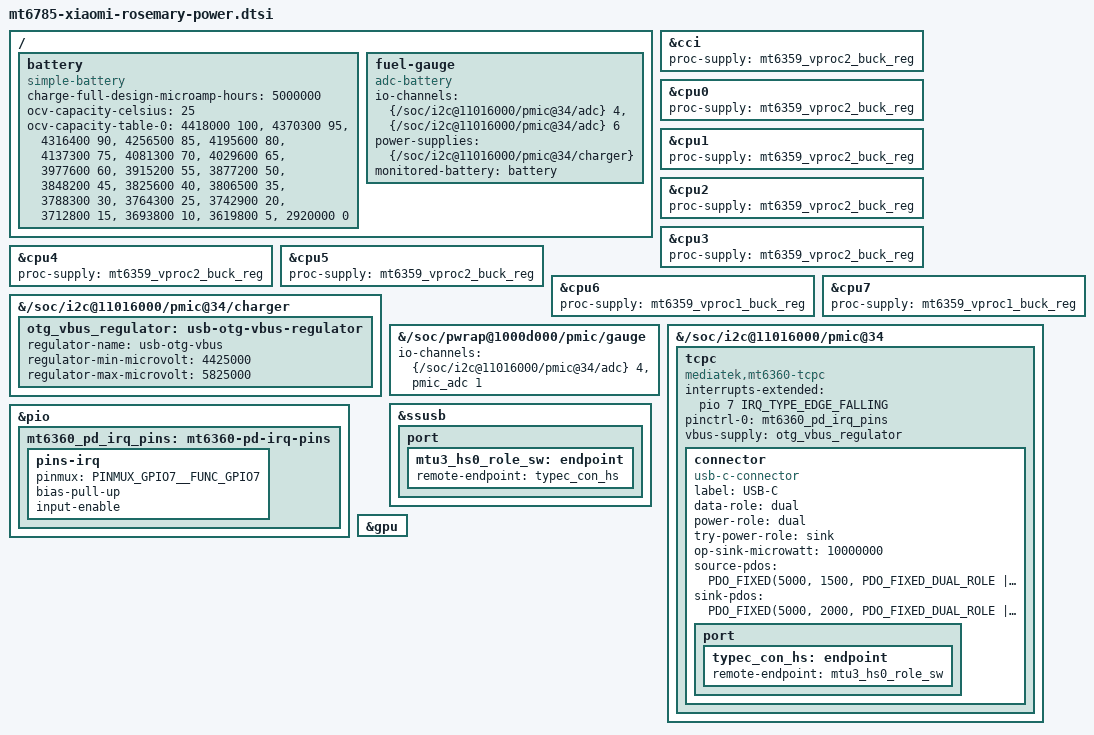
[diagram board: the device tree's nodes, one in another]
// SPDX-License-Identifier: GPL-2.0-only
/*
 * Poco M5s (rosemary): board nodes of the power area (poco-m5s/plan-full-phone.md, Task 0.3).
 * Included at the end of mt6785-xiaomi-rosemary.dts.
 */

#include <dt-bindings/usb/pd.h>

/ {
	/*
	 * The pack: 5000 mAh design (the stock gauge reported 4797 mAh full, 12.11.2026). OCV table:
	 * the vendor profile battery0_profile_t1 (25 C) of the live stock DT (bat_gm30), sampled at 5 %
	 * steps, the same table poco-charge-limit uses.
	 */
	battery: battery {
		compatible = "simple-battery";
		charge-full-design-microamp-hours = <5000000>;
		ocv-capacity-celsius = <25>;
		ocv-capacity-table-0 = <4418000 100>, <4370300 95>, <4316400 90>, <4256500 85>,
				       <4195600 80>, <4137300 75>, <4081300 70>, <4029600 65>,
				       <3977600 60>, <3915200 55>, <3877200 50>, <3848200 45>,
				       <3825600 40>, <3806500 35>, <3788300 30>, <3764300 25>,
				       <3742900 20>, <3712800 15>, <3693800 10>, <3619800 5>,
				       <2920000 0>;
	};

	/*
	 * Battery voltage and current until the MT6359 coulomb counter lands: the MT6360 ADC's VBAT and
	 * IBAT channels (drivers/iio/adc/mt6360-adc.c enum: VBAT = 4, IBAT = 6), read on the phone
	 * 15.11.2026 as 4.376 V and 0 A with the charger reporting Full.
	 */
	fuel-gauge {
		compatible = "adc-battery";
		io-channels = <&{/soc/i2c@11016000/pmic@34/adc} 4>, <&{/soc/i2c@11016000/pmic@34/adc} 6>;
		io-channel-names = "voltage", "current";
		power-supplies = <&{/soc/i2c@11016000/pmic@34/charger}>;
		monitored-battery = <&battery>;
	};
};

/*
 * CPU and CCI supplies, as the begonia board on the same SoC and PMIC wires them
 * (mt6785-xiaomi-begonia-common.dtsi): little cores 0-5 and the CCI on MT6359 VPROC2 ("vproc_l" in
 * the rosemary dts), big cores 6-7 on VPROC1 ("vproc_b"). Without them mediatek-cpufreq and
 * mtk-ccifreq never probe (no cpufreq on the phone, ccifreq deferred, 15.11.2026).
 */
&cci { proc-supply = <&mt6359_vproc2_buck_reg>; };
&cpu0 { proc-supply = <&mt6359_vproc2_buck_reg>; };
&cpu1 { proc-supply = <&mt6359_vproc2_buck_reg>; };
&cpu2 { proc-supply = <&mt6359_vproc2_buck_reg>; };
&cpu3 { proc-supply = <&mt6359_vproc2_buck_reg>; };
&cpu4 { proc-supply = <&mt6359_vproc2_buck_reg>; };
&cpu5 { proc-supply = <&mt6359_vproc2_buck_reg>; };
&cpu6 { proc-supply = <&mt6359_vproc1_buck_reg>; };
&cpu7 { proc-supply = <&mt6359_vproc1_buck_reg>; };

/*
 * USB Type-C: the MT6360 TCPC (I2C5 0x4e in the vendor DT, usb_type_c@4e; its PD interrupt on GPIO7,
 * live DT type_c_port0 mt6360pd,intr_gpio = <&pio 7 0>) drives the role switch of the USB controller
 * and the OTG boost of the MT6360 charger. Written as on begonia (mt6785-xiaomi-begonia-common.dtsi),
 * the same SoC with the same MT6360: dual role, sink preferred, 5 V only both ways. Without it the
 * port is fixed to peripheral and USB OTG cannot work.
 */
&{/soc/i2c@11016000/pmic@34/charger} {
	otg_vbus_regulator: usb-otg-vbus-regulator {
		regulator-name = "usb-otg-vbus";
		regulator-min-microvolt = <4425000>;
		regulator-max-microvolt = <5825000>;
	};
};

/*
 * The gauge takes the battery voltage from the same converter the generic
 * adc-battery reads: the MT6360's ADC, channel 4 ("voltage" there). The MT6359's own
 * ADC has the same channel numbering but different channels, and reading channel 4
 * of it gave a constant 9.153 V.
 */
&{/soc/pwrap@1000d000/pmic/gauge} {
	io-channels = <&{/soc/i2c@11016000/pmic@34/adc} 4>, <&pmic_adc 1>;
	io-channel-names = "vbat", "ntc";
};

&{/soc/i2c@11016000/pmic@34} {
	tcpc {
		compatible = "mediatek,mt6360-tcpc";
		interrupts-extended = <&pio 7 IRQ_TYPE_EDGE_FALLING>;
		interrupt-names = "PD_IRQB";
		pinctrl-names = "default";
		pinctrl-0 = <&mt6360_pd_irq_pins>;
		vbus-supply = <&otg_vbus_regulator>;

		connector {
			compatible = "usb-c-connector";
			label = "USB-C";
			data-role = "dual";
			power-role = "dual";
			try-power-role = "sink";
			op-sink-microwatt = <10000000>;
			source-pdos = <PDO_FIXED(5000, 1500, PDO_FIXED_DUAL_ROLE | PDO_FIXED_DATA_SWAP)>;
			sink-pdos = <PDO_FIXED(5000, 2000, PDO_FIXED_DUAL_ROLE | PDO_FIXED_DATA_SWAP)>;

			port {
				typec_con_hs: endpoint {
					remote-endpoint = <&mtu3_hs0_role_sw>;
				};
			};
		};
	};
};

&pio {
	mt6360_pd_irq_pins: mt6360-pd-irq-pins {
		pins-irq {
			pinmux = <PINMUX_GPIO7__FUNC_GPIO7>;
			bias-pull-up;
			input-enable;
		};
	};
};

&ssusb {
	port {
		mtu3_hs0_role_sw: endpoint {
			remote-endpoint = <&typec_con_hs>;
		};
	};
};

/*
 * 3D: the Mali-G76 MC4 through panfrost (mediatek_mt6785_data). The supplies are already in the main dts
 * (mali VGPU11, MFG domain VPU buck, as on begonia, where the same node is enabled upstream).
 */
&gpu {
	status = "okay";
};
